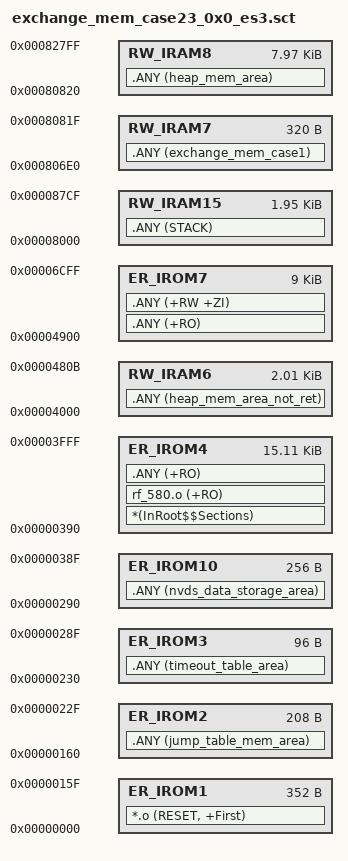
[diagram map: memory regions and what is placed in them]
; *************************************************************
; *** Scatter-Loading Description File generated by uVision ***
; *************************************************************

LR_IROM1 0x00000000 0x00005000 {  ; load region size_region
  ER_IROM1 0x00000000 0x00000160  {  ; load address = execution address
   *.o (RESET, +First)
;   *(InRoot$$Sections)
  }
}
 
LR_IROM2  0x00000160 0x00d0 {
ER_IROM2 0x00000160 0x00d0  {
   .ANY (jump_table_mem_area) 
	
  }
}

LR_IROM3 0x00000230 0x060 {
 ER_IROM3 0x00000230 0x060  {
   .ANY (timeout_table_area)
  }
}

LR_IROM10 0x00000290 0x0100 {
 ER_IROM10 0x00000290 0x0100  {
   .ANY (nvds_data_storage_area)
  }
}

LR_IROM4  0x00000390 0x3c70 {
ER_IROM4 0x00000390 0x3c70  {
   *(InRoot$$Sections)
	rf_580.o (+RO)
;	llm.o(+RO)
	.ANY (+RO) 
    
  	
  }
}  

LR_IRAM5  0x00004000 0x00006800 {
  
;RW_IRAM6 0x00004000 0x00003800 {
RW_IRAM6 0x00004000 0x000080c  {
   .ANY (heap_mem_area_not_ret)    
 }
}

LR_IROM7  0x00004900 0x2400 {			
ER_IROM7 0x00004900 0x2400  {
	.ANY (+RO)
	.ANY (+RW +ZI)
}

RW_IRAM15 0x00008000 0x000007d0 {  ; RW data
   .ANY (STACK)
  }


;RW_IRAM5 0x00009020 0x000007d0 {  ; RW data
;.ANY (+RW +ZI)
;hardfault_handler.o (+RW +ZI)
;   .ANY (STACK)
;  }


;RW_IRAM5 0x00009000 0x000007f0   {  ; RW data
;   .ANY (+RW +ZI)
;   .ANY (STACK)
;  }


RW_IRAM7 0x0000806e0  0x00000140  {
   .ANY (exchange_mem_case1) 
 }

RW_IRAM8 0x000080820 0x00001FE0  {
    .ANY (heap_mem_area)
  }  
}

